# TC37XPD register map
Vendor: Infineon; Series: ATVMC; File version: 100
CPU: other r0p0, little endian, MPU, FPU, vendor SysTick, 4 interrupt priority bits
Registers are 32-bit, read-write, reset 0x0 unless marked. A register's access mark holds for its fields unless they carry their own. Offsets are from the block's base; [hi:lo] are bit positions; lines under a group give offsets from that group; {n}, {i} and the like mark numbered series; 'fields as' and 'values as' point back to an identical list.

## CPU0 (part 2 of 2) — CPU
Base 0xF8800000
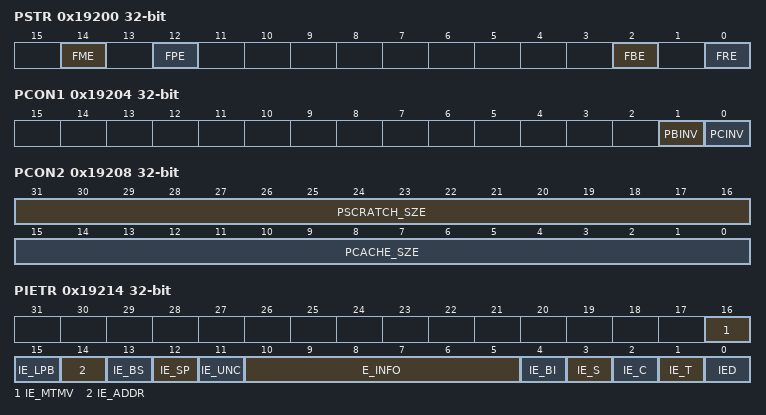
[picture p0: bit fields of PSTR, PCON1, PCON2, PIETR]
0x19200 PSTR — CPUx Program Synchronous Trap Register resetvalue={Application Reset:0x0}
  [14] FME — Fetch MSIST Error FME. During SIST mode a fetch from the PTAG will cause a PSE trap to occur.
  [12] FPE — Fetch Peripheral Error FPE. A Fetch peripheral error will be flagged whenever a fetch is attempted to peripheral space.
  [2] FBE — Fetch Bus Error FBE. A Fetch bus error will be set whenever the SRI flags an error due a fetch from external memory. This will be set for both direct fetches from the bus and for cache refills.
  [0] FRE — Fetch Range Error FRE. A Fetch Range Error occurs whenever an access to the Program Scratch is outside the range of the SRAM.
0x19204 PCON1 — CPUx Program Control 1 resetvalue={Application Reset:0x0}
  [1] PBINV — Program Buffer Invalidate PBINV. Write Operation This field returns 0 when read.
  [0] PCINV — Program Cache Invalidate PCINV
0x19208 PCON2 ro reset not defined — CPUx Program Control 2 resetvalue={Application Reset:0x0}
  [31:16] PSCRATCH_SZE — Program Scratch Size in KBytes PSCRATCH SZE. In KBytes
  [15:0] PCACHE_SZE — Program Cache Size ICACHE in KBytes PCACHE SZE. In KBytes
0x1920C PCON0 reset 0x2 — CPUx Program Control 0 resetvalue={Application Reset:0x2}
  [1] PCBYP — Program Cache Bypass PCBYP
0x19210 PIEAR ro — CPUx Program Integrity Error Address Register resetvalue={Application Reset:0x0}
  [31:0] TA — Transaction Address TA. Physical address being accessed by operation that encountered program integrity error.
0x19214 PIETR access per field — CPUx Program Integrity Error Trap Register resetvalue={Application Reset:0x0}
  [16] IE_MTMV ro — Memory Test Mode Violation detected IE MTMV
  [15] IE_LPB ro — Integrity Error Local Pflash bank IE LPB
  [14] IE_ADDR ro — Address Phase error detected at SRI slave interface IE ADDR
  [13] IE_BS ro — Bus Slave Access Indicator IE BS
  [12] IE_SP ro — Safety Protection Error Detected IE SP
  [11] IE_UNC ro — Integrity Error Uncorrectable Error Detected IE UNC
  [10:5] E_INFO ro — Error Information E INFO. If IE BS 1 Bus Master Tag ID of requesting masterIf IE C 1 Cache way.
  [4] IE_BI ro — Integrity Error Bus Interface IE BI
  [3] IE_S ro — Integrity Error Scratchpad Memory IE S
  [2] IE_C ro — Integrity Error Cache Memory IE C
  [1] IE_T ro — Integrity Error TAG Memory IE T
  [0] IED rw — Integrity Error Detected IED
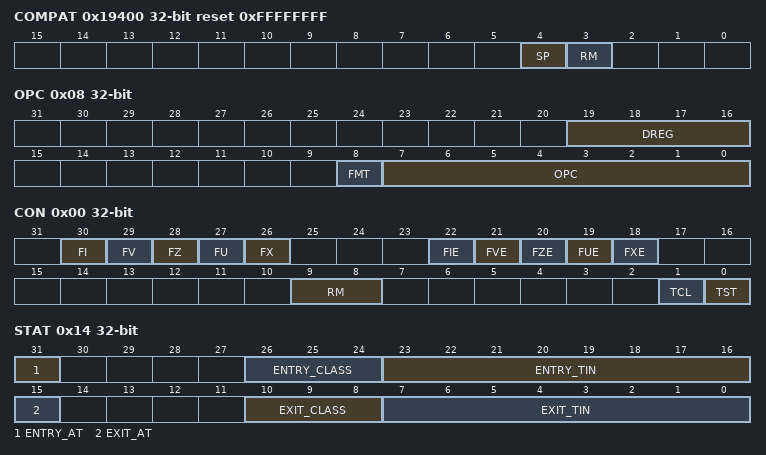
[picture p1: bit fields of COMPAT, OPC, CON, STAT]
0x19400 COMPAT reset 0xFFFFFFFF — CPUx Compatibility Control Register resetvalue={Application Reset:0x0FFFFFFFF}
  [4] SP — SYSCON Safety Protection Mode Compatibility SP
  [3] RM — Rounding Mode Compatibility RM
0x1A000 FPU_TRAP group
  0x00 CON access per field — CPUx Trap Control Register resetvalue={Application Reset:0x0}
    [30] FI ro — Captured FI FI. Asserted if the captured instruction asserted FI. Only valid when TST is asserted
    [29] FV ro — Captured FV FV. Asserted if the captured instruction asserted FV. Only valid when TST is asserted
    [28] FZ ro — Captured FZ FZ. Asserted if the captured instruction asserted FZ. Only valid when TST is asserted
    [27] FU ro — Captured FU FU. Asserted if the captured instruction asserted FU. Only valid when TST is asserted.
    [26] FX ro — Captured FX FX. Asserted if the captured instruction asserted FX. Only valid when TST is asserted.
    [22] FIE rw — FI Trap Enable FIE. When set an instruction generating an FI exception will trigger a trap.
    [21] FVE rw — FV Trap Enable FVE. When set an instruction generating an FV exception will trigger a trap.
    [20] FZE rw — FZ Trap Enable FZE. When set an instruction generating an FZ exception will trigger a trap.
    [19] FUE rw — FU Trap Enable FUE. When set an instruction generating an FU exception will trigger a trap.
    [18] FXE rw — FX Trap Enable FXE. When set an instruction generating an FX exception will trigger a trap.
    [9:8] RM ro — Captured Rounding Mode RM. The rounding mode of the captured instruction. Only valid when TST is asserted. Note that this is the rounding mode supplied to the FPU for the exceptional instruction. UPDFL instructions may cause a trap and change the rounding mode. In this case the RM bits capture the input rounding mode
    [1] TCL wo — Trap Clear TCL. Read always reads as 0.
    [0] TST ro — Trap Status TST
  0x04 PC ro — CPUx Trapping Instruction Program Counter Register resetvalue={Application Reset:0x0}
    [31:0] PC — Captured Program Counter PC. The program counter virtual address of the captured instruction. Only valid when FPU TRAP CON.TST is asserted.
  0x08 OPC ro — CPUx Trapping Instruction Opcode Register resetvalue={Application Reset:0x0}
    [19:16] DREG — Captured Destination Register DREG. The destination register of the captured instruction. ... Only valid when FPU TRAP CON.TST is asserted.
    [8] FMT — Captured Instruction Format FMT. The format of the captured instruction s opcode. Only valid when FPU TRAP CON.TST is asserted.
    [7:0] OPC — Captured Opcode OPC. The secondary opcode of the captured instruction. When FPU TRAP OPC.FMT 0 only bits 3 0 are defined. OPC is valid only when FPU TRAP CON.TST is asserted.
  0x10 SRC1 ro — CPUx Trapping Instruction Operand Register resetvalue={Application Reset:0x0}
    [31:0] SRC1 — Captured SRC1 Operand SRC1. The SRC1 operand of the captured instruction. Only valid when FPU TRAP CON.TST is asserted.
  0x14 SRC2 ro — CPUx Trapping Instruction Operand Register resetvalue={Application Reset:0x0}
    [31:0] SRC2 — Captured SRC2 Operand SRC2. The SRC2 operand of the captured instruction. Only valid when FPU TRAP CON.TST is asserted.
  0x18 SRC3 ro — CPUx Trapping Instruction Operand Register resetvalue={Application Reset:0x0}
    [31:0] SRC3 — Captured SRC3 Operand SRC3. The SRC3 operand of the captured instruction. Only valid when FPU TRAP CON.TST is asserted.
{0x1C000+8i} DPR[{i}] (i=0..17) group
  0x00 DPRy_L — CPUx Data Protection Range 0 Lower Bound Register resetvalue={Application Reset:0x0}
    [31:3] LOWBND — DPRy Lower Boundary Address LOWBND
  0x04 DPRy_U — CPUx Data Protection Range 0 Upper Bound Register resetvalue={Application Reset:0x0}
    [31:3] UPPBND — DPRy Upper Boundary Address UPPBND
{0x1D000+8i} CPR[{i}] (i=0..9) group
  0x00 CPRy_L — CPUx Code Protection Range 0 Lower Bound Register resetvalue={Application Reset:0x0}
    [31:5] LOWBND — CPRy Lower Boundary Address LOWBND
  0x04 CPRy_U — CPUx Code Protection Range 0 Upper Bound Register resetvalue={Application Reset:0x0}
    [31:5] UPPBND — CPR0 m Upper Boundary Address UPPBND
0x1E000 CPXE_0 — CPUx Code Protection Execute Enable Register Set 3 resetvalue={Application Reset:0x0}
  [9:0] XE_n — Execute Enable Range select XE n
0x1E004 CPXE_1 — CPUx Code Protection Execute Enable Register Set 3 resetvalue={Application Reset:0x0}
  [9:0] XE_n — Execute Enable Range select XE n
0x1E008 CPXE_2 — CPUx Code Protection Execute Enable Register Set 3 resetvalue={Application Reset:0x0}
  [9:0] XE_n — Execute Enable Range select XE n
0x1E00C CPXE_3 — CPUx Code Protection Execute Enable Register Set 3 resetvalue={Application Reset:0x0}
  [9:0] XE_n — Execute Enable Range select XE n
0x1E010 DPRE_0 — CPUx Data Protection Read Enable Register Set 3 resetvalue={Application Reset:0x0}
  [17:0] RE_n — Read Enable Range Select RE n
0x1E014 DPRE_1 — CPUx Data Protection Read Enable Register Set 3 resetvalue={Application Reset:0x0}
  [17:0] RE_n — Read Enable Range Select RE n
0x1E018 DPRE_2 — CPUx Data Protection Read Enable Register Set 3 resetvalue={Application Reset:0x0}
  [17:0] RE_n — Read Enable Range Select RE n
0x1E01C DPRE_3 — CPUx Data Protection Read Enable Register Set 3 resetvalue={Application Reset:0x0}
  [17:0] RE_n — Read Enable Range Select RE n
0x1E020 DPWE_0 — CPUx Data Protection Write Enable Register Set 3 resetvalue={Application Reset:0x0}
  [17:0] WE_n — Write Enable Range Select WE n
0x1E024 DPWE_1 — CPUx Data Protection Write Enable Register Set 3 resetvalue={Application Reset:0x0}
  [17:0] WE_n — Write Enable Range Select WE n
0x1E028 DPWE_2 — CPUx Data Protection Write Enable Register Set 3 resetvalue={Application Reset:0x0}
  [17:0] WE_n — Write Enable Range Select WE n
0x1E02C DPWE_3 — CPUx Data Protection Write Enable Register Set 3 resetvalue={Application Reset:0x0}
  [17:0] WE_n — Write Enable Range Select WE n
0x1E040 CPXE_4 — CPUx Code Protection Execute Enable Register Set 5 resetvalue={Application Reset:0x0}
  [9:0] XE_n — Execute Enable Range select XE n
0x1E044 CPXE_5 — CPUx Code Protection Execute Enable Register Set 5 resetvalue={Application Reset:0x0}
  [9:0] XE_n — Execute Enable Range select XE n
0x1E050 DPRE_4 — CPUx Data Protection Read Enable Register Set 5 resetvalue={Application Reset:0x0}
  [17:0] RE_n — Read Enable Range Select RE n
0x1E054 DPRE_5 — CPUx Data Protection Read Enable Register Set 5 resetvalue={Application Reset:0x0}
  [17:0] RE_n — Read Enable Range Select RE n
0x1E060 DPWE_4 — CPUx Data Protection Write Enable Register Set 5 resetvalue={Application Reset:0x0}
  [17:0] WE_n — Write Enable Range Select WE n
0x1E064 DPWE_5 — CPUx Data Protection Write Enable Register Set 5 resetvalue={Application Reset:0x0}
  [17:0] WE_n — Write Enable Range Select WE n
0x1E400 TPS group
  0x00 CON ro — CPUx Temporal Protection System Control Register resetvalue={Application Reset:0x0}
    [16] TTRAP — Temporal Protection Trap TTRAP. If set indicates that a TAE trap has been requested. Any subsequent TAE traps are disabled. A write clears the flag and re enables TAE traps.
    [2] TEXP2 — Timer1 Expired Flag TEXP2. Set when the corresponding timer expires. Cleared on any write to the TIMER1 register.
    [1] TEXP1 — Timer1 Expired Flag TEXP1. Set when the corresponding timer expires. Cleared on any write to the TIMER1 register.
    [0] TEXP0 — Timer0 Expired Flag TEXP0. Set when the corresponding timer expires. Cleared on any write to the TIMER0 register.
  {0x4+4j} TIMER[{j}] (j=0..2) — CPUx Temporal Protection System Timer Register 0 resetvalue={Application Reset:0x0}
    [31:0] Timer — Temporal Protection Timer Timer. Writing zero de activates the Timer. Writing a non zero value starts the Timer. Any write clears the corresponding TPS CON.TEXP flag. Read returns the current Timer value.
0x1E440 TPS_EXTIM group
  0x00 ENTRY_LVAL — CPUx Exception Entry Timer Load Value resetvalue={Application Reset:0x0}
    [11:4] ENTRY_LVAL — Exception Entry Timer Load value ENTRY LVAL. Value loaded into the exception entry timer on detection of an enabled exception. Bits 3 0 are constrained to be 0
  0x04 ENTRY_CVAL ro — CPUx Exception Entry Timer Current Value resetvalue={Application Reset:0x0}
    [11:0] ENTRY_CVAL — Exception Entry Timer Current Value ENTRY CVAL. Current value of the exception entry timer.
  0x08 EXIT_LVAL — CPUx Exception Exit Timer Load Value resetvalue={Application Reset:0x0}
    [23:4] EXIT_LVAL — Exception Exit Timer Load value EXIT LVAL. Value loaded into the exception exit timer on detection of an enabled exception. Bits 3 0 are constrained to be 0
  0x0C EXIT_CVAL ro — CPUx Exception Exit Timer Current Value resetvalue={Application Reset:0x0}
    [23:0] EXIT_CVAL — Exception Exit Timer Current Value EXIT CVAL. Current value of the exception exit timer.
  0x10 CLASS_EN — CPUx Exception Timer Class Enable Register resetvalue={Application Reset:0x0}
    [7:0] EXTIM_CLASS_EN — Exception Timer Class Enables EXTIM CLASS EN. Trap Class enables for exception timer.
  0x14 STAT access per field — CPUx Exception Timer Status Register resetvalue={Application Reset:0x0}
    [31] ENTRY_AT ro — Exception Entry Timer Alarm Triggered ENTRY AT. Exception Entry Timer Alarm triggered sticky bit. Alarm triggered since last cleared.
    [26:24] ENTRY_CLASS rw — Exception Entry Timer Class ENTRY CLASS. Exception Entry Timer Class of triggering trap.
    [23:16] ENTRY_TIN rw — Exception Entry Timer TIN ENTRY TIN. Exception Entry Timer TIN of triggering trap.
    [15] EXIT_AT ro — Exception Exit Timer Alarm Triggered EXIT AT. Exception Exit Timer Alarm triggered sticky bit. Alarm triggered since last cleared.
    [10:8] EXIT_CLASS rw — Exception Exit Timer Class EXIT CLASS. Exception exit Timer Class of triggering trap.
    [7:0] EXIT_TIN rw — Exception Exit Timer TIN EXIT TIN. Exception Exit Timer TIN of triggering trap.
  0x18 FCX ro — CPUx Exception Timer FCX Register resetvalue={Application Reset:0x0}
    [19:0] EXIT_FCX — Exception Exit Timer FCX EXIT FCX. Exception Exit Timer FCX of triggering trap.
{0x1F000+8i} TR[{i}] (i=0..7) group — Trigger
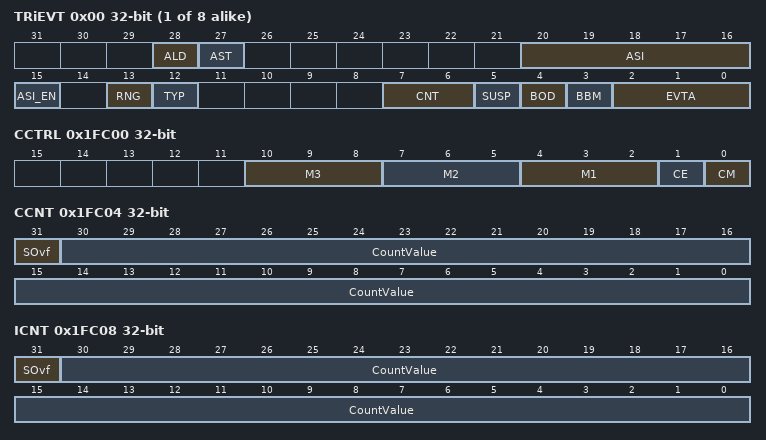
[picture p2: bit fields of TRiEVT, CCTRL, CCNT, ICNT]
  0x00 TRiEVT — CPUx Trigger Event 0 resetvalue={Debug Reset:0x0}
    [28] ALD — Address Load ALD. Used in conjunction with TYP 0
    [27] AST — Address Store AST. Used in conjunction with TYP 0
    [20:16] ASI — Address Space Identifier ASI. The ASI of the Debug Trigger process.
    [15] ASI_EN — Enable ASI Comparison ASI EN
    [13] RNG — Compare Type RNG. Once an even numbered comparator has been set to range the EVTR settings of its associated upper neighbour will be ignored.
    [12] TYP — Input Selection TYP
    [7:6] CNT — Counter CNT. When this event occurs adjust the control of the performance counters in task mode as follows
    [5] SUSP — CDC Suspend Out Signal State SUSP. Value to be assigned to the CDC suspend out signal when the Debug Event is raised.
    [4] BOD — Breakout Disable BOD
    [3] BBM — Break Before Make BBM or Break After Make BAM Selection BBM. Code triggers BBM or BAM selection. Data access and data code combination access triggers can only create BAM Debug Events. When these triggers occur TRnEVT.BBM is ignored.
    [2:0] EVTA — Event Associated EVTA. Specifies the Debug Action associated with the Debug Event
  0x04 TRiADR — CPUx Trigger Address 0 resetvalue={Debug Reset:0x0}
    [31:0] ADDR — Comparison Address ADDR. For PC comparison bit 0 is always zero.
0x1FC00 CCTRL — CPUx Counter Control resetvalue={Debug Reset:0x0}
  [10:8] M3 — M3CNT Configuration M3
  [7:5] M2 — M2CNT Configuration M2
  [4:2] M1 — M1CNT Configuration M1
  [1] CE — Count Enable CE
  [0] CM — Counter Mode CM
0x1FC04 CCNT — CPUx CPU Clock Cycle Count resetvalue={Debug Reset:0x0}
  [31] SOvf — Sticky Overflow Bit SOvf. This bit is set by hardware when count value 30 0 31 h7FFF FFFF. It can only be cleared by software.
  [30:0] CountValue — Count Value CountValue. Current Count of the CPU Clock Cycles.
0x1FC08 ICNT — CPUx Instruction Count resetvalue={Debug Reset:0x0}
  [31] SOvf — Sticky Overflow Bit SOvf. This bit is set by hardware when count value 30 0 31 h7FFF FFFF. It can only be cleared by software.
  [30:0] CountValue — Count Value CountValue. Count of the Instructions Executed.
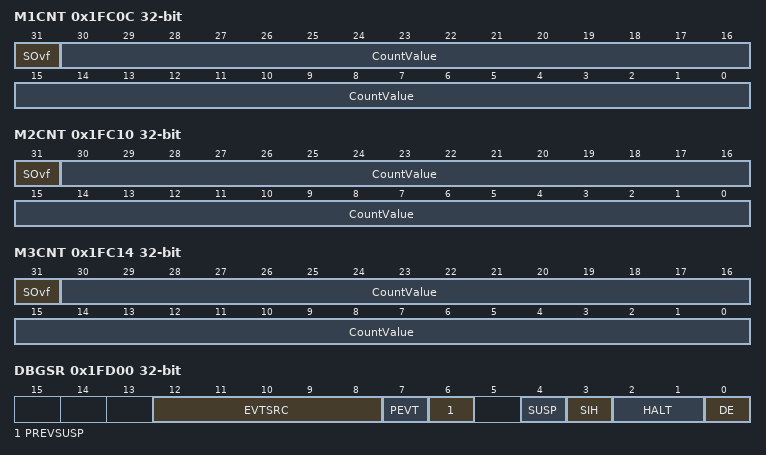
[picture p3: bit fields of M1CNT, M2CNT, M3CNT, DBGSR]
0x1FC0C M1CNT — CPUx Multi Count Register 1 resetvalue={Debug Reset:0x0}
  [31] SOvf — Sticky Overflow Bit SOvf. This bit is set by hardware when count value 30 0 31 h7FFF FFFF. It can only be cleared by software.
  [30:0] CountValue — Count Value CountValue. Count of the Selected Event.
0x1FC10 M2CNT — CPUx Multi Count Register 2 resetvalue={Debug Reset:0x0}
  fields as M1CNT
0x1FC14 M3CNT — CPUx Multi Count Register 3 resetvalue={Debug Reset:0x0}
  fields as M1CNT
0x1FD00 DBGSR access per field — CPUx Debug Status Register resetvalue={Debug Reset:0x0}
  [12:8] EVTSRC ro — Event Source EVTSRC. ... Other Reserved.
  [7] PEVT rw — Posted Event PEVT
  [6] PREVSUSP ro — Previous State of Core Suspend Out Signal PREVSUSP. Updated when a Debug Event causes a hardware update of DBGSR.SUSP. This field is not updated for writes to DBGSR.SUSP.
  [4] SUSP rw — Current State of the Core Suspend Out Signal SUSP
  [3] SIH ro — Suspend in Halt SIH. State of the Suspend In signal.
  [2:1] HALT rw — CPU Halt Request Status Field HALT. HALT can be set or cleared by software. HALT 0 is the actual Halt bit. HALT 1 is a mask bit to specify whether or not HALT 0 is to be updated on a software write. HALT 1 is always read as 0. HALT 1 must be set to 1 in order to update HALT 0 by software R read W write .
  [0] DE ro — Debug Enable DE. Determines whether the CDC is enabled or not.
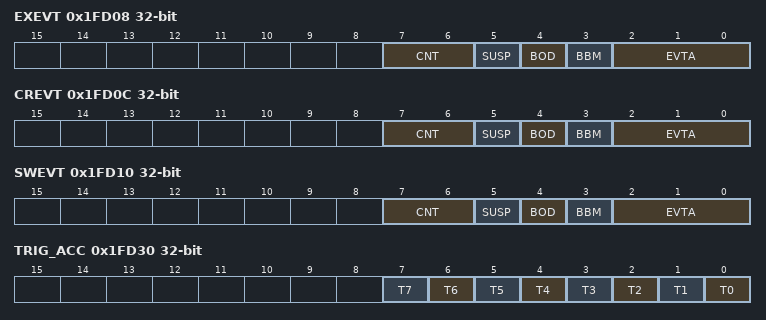
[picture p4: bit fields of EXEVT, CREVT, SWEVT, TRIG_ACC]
0x1FD08 EXEVT — CPUx External Event Register resetvalue={Debug Reset:0x0}
  [7:6] CNT — Counter CNT. When this event occurs adjust the control of the performance counters in task mode as follows
  [5] SUSP — CDC Suspend Out Signal State SUSP. Value to be assigned to the CDC suspend out signal when the Debug Event is raised.
  [4] BOD — Breakout Disable BOD
  [3] BBM — Break Before Make BBM or Break After Make BAM Selection BBM
  [2:0] EVTA — Event Associated EVTA. Specifies the Debug Action associated with the Debug Event
0x1FD0C CREVT — CPUx Core Register Access Event resetvalue={Debug Reset:0x0}
  [7:6] CNT — Counter CNT. When this event occurs adjust the control of the performance counters in task mode as follows
  [5] SUSP — CDC Suspend Out Signal State SUSP. Value to be assigned to the CDC suspend out signal when the Debug Event is raised.
  [4] BOD — Breakout Disable BOD
  [3] BBM — Break Before Make BBM or Break After Make BAM Selection BBM
  [2:0] EVTA — Event Associated EVTA. Debug Action associated with the Debug Event
0x1FD10 SWEVT — CPUx Software Debug Event resetvalue={Debug Reset:0x0}
  [7:6] CNT — Counter CNT. When this event occurs adjust the control of the performance counters in task mode as follows
  [5] SUSP — CDC Suspend Out Signal State SUSP. Value to be assigned to the CDC suspend out signal when the event is raised.
  [4] BOD — Breakout Disable BOD
  [3] BBM — Break Before Make BBM or Break After Make BAM Selection BBM
  [2:0] EVTA — Event Associated EVTA. Debug Action associated with the Debug Event
0x1FD30 TRIG_ACC ro — CPUx TriggerAddressx resetvalue={Debug Reset:0x0}
  [n] T{n} (n=0..7) — Trigger {n} T{n}. active since last cleared
0x1FD40 DMS reset 0xA0000A00 (reset mask 0xFFFFFE3F) — CPUx Debug Monitor Start Address resetvalue={Debug Reset:0x0A0000A00}
  [31:1] DMSValue — Debug Monitor Start Address DMSValue. The address at which monitor code execution begins when a breakpoint trap is taken.
0x1FD44 DCX reset 0xA0000200 (reset mask 0xFFFFFE3F) — CPUx Debug Context Save Area Pointer resetvalue={Debug Reset:0x0A0000200}
  [31:6] DCXValue — Debug Context Save Area Pointer DCXValue. Address where the debug context is stored following a breakpoint trap.
0x1FD48 DBGTCR reset 0x1 — CPUx Debug Trap Control Register resetvalue={Application Reset:0x1}
  [0] DTA — Debug Trap Active Bit DTA. A breakpoint trap may only be taken in the condition DTA 0. Taking a breakpoint trap sets the DTA bit to one. Further breakpoint traps are therefore disabled until such time as the breakpoint trap handler clears the DTA bit or until the breakpoint trap handler terminates with a RFM.
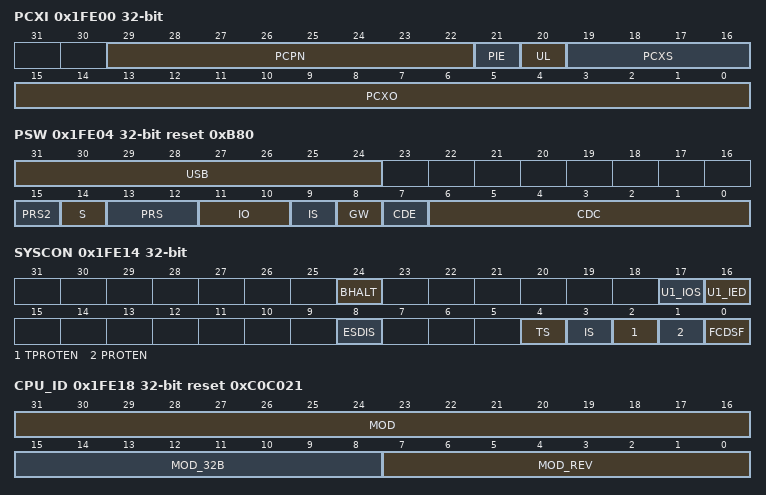
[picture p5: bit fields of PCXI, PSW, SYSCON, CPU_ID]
0x1FE00 PCXI — CPUx Previous Context Information Register resetvalue={Application Reset:0x0}
  [29:22] PCPN — Previous CPU Priority Number PCPN. Contains the priority level number of the interrupted task.
  [21] PIE — Previous Interrupt Enable PIE. Indicates the state of the interrupt enable bit ICR.IE for the interrupted task.
  [20] UL — Upper or Lower Context Tag UL. Identifies the type of context saved. If the type does not match the type expected when a context restore operation is performed a trap is generated.
  [19:16] PCXS — Previous Context Pointer Segment Address PCXS. Contains the segment address portion of the PCX. This field is used in conjunction with the PCXO field.
  [15:0] PCXO — Previous Context Pointer Offset Field PCXO. The PCXO and PCXS fields form the pointer PCX which points to the CSA of the previous context.
0x1FE04 PSW reset 0xB80 — CPUx Program Status Word resetvalue={Application Reset:0x0B80}
  [31:24] USB — User Status Bits USB. The eight most significant bits of the PSW are designated as User Status Bits. These bits may be set or cleared as side effects of instruction execution. Refer to the TriCore Architecture manual for details.
  [15] PRS2 — Protection Register Set MSB PRS2. Selects the active Data and Code Memory Protection Register Set. The memory protection register values control load store and instruction fetches within the current process. PRS values 111 and 110 are reserved
  [14] S — Safe Task Identifier S
  [13:12] PRS — Protection Register Set PRS. Selects the active Data and Code Memory Protection Register Set. The memory protection register values control load store and instruction fetches within the current process. PRS values 111 and 110 are reserved
  [11:10] IO — Access Privilege Level Control I O Privilege IO. Determines the access level to special function registers and peripheral devices.
  [9] IS — Interrupt Stack Control IS. Determines if the current execution thread is using the shared global interrupt stack or a user stack.
  [8] GW — Global Address Register Write Permission GW. Determines whether the current execution thread has permission to modify the global address registers.Most tasks and ISRs use the global address registers as read only registers pointing to the global literal pool and key data structures. However a task or ISR can be designated as the owner of a particular global address register and is allowed to modify it. The system designer must determine which global address variables are used with sufficient frequency and or in sufficiently time critical code to justify allocation to a global address register. By compiler convention global address register A 0 is reserved as the base register for short form loads and stores. Register A 1 is also reserved for compiler use.Registers A 8 and A 9 are not used by the compiler and are available for holding critical system address variables.
  [7] CDE — Call Depth Count Enable CDE. Enables call depth counting provided that the PSW.CDC mask field is not all set to 1. If PSW.CDC 1111111 B call depth counting is disabled regardless of the setting on the PSW.CDE bit.
  [6:0] CDC — Call Depth Counter CDC. Consists of two variable width subfields. The first subfield consists of a string of zero or more initial 1 bits terminated by the first 0 bit. The remaining bits form the second subfield CDC.COUNT which constitutes the Call Depth Count value. The count value is incremented on each Call and is decremented on a Return. 0cccccc B 6 bit counter trap on overflow. 10ccccc B 5 bit counter trap on overflow. 110cccc B 4 bit counter trap on overflow. 1110ccc B 3 bit counter trap on overflow. 11110cc B 2 bit counter trap on overflow. 111110c B 1 bit counter trap on overflow. 1111110 B Trap every call Call Trace mode . 1111111 B Disable Call Depth Counting. When the call depth count CDC.COUNT overflows a trap CDO is generated. Setting the CDC to 1111110 B allows no bits for the counter and causes every call to be trapped. This is used for Call Depth Tracing. Setting the CDC to 1111111 B disables Call Depth Counting.
0x1FE08 PC reset not defined — CPUx Program Counter resetvalue={Application Reset:0x0}
  [31:1] PC — Program Counter PC
0x1FE14 SYSCON reset not defined — CPUx System Configuration Register resetvalue={Application Reset:0x0,Application Reset:0x0}
  [24] BHALT — Boot Halt BHALT
  [17] U1_IOS — User 1 Peripheral access as supervisor U1 IOS. Allow User 1 mode tasks to access peripherals as if in Supervisor mode. Enables User 1 access to all peripheral registers.
  [16] U1_IED — User 1 Instruction execution disable U1 IED. Disable the execution of User 1 mode instructions in User 1 IO mode. Disables User 1 ability to enable and disable interrupts.
  [8] ESDIS — Emulator Space Disable. Disable the Emulator Space system
  [4] TS — Initial State Trap TS. of PSW.S bit in trap handle
  [3] IS — Initial State Interrupt IS. of PSW.S bit in interrupt handle
  [2] TPROTEN — Temporal Protection Enable TPROTEN. Enable the Temporal Protection system.
  [1] PROTEN — Memory Protection Enable PROTEN. Enables the memory protection system. Memory protection is controlled through the memory protection register sets. Note Initialize the protection register sets prior to setting PROTEN to one.
  [0] FCDSF — Free Context List Depleted Sticky Flag FCDSF. This sticky bit indicates that a FCD Free Context List Depleted trap occurred since the bit was last cleared by software.
0x1FE18 CPU_ID ro reset 0xC0C021 — CPUx Identification Register TC1.6.2P resetvalue={Application Reset:0x0C0C021}
  [31:16] MOD — Module Identification Number MOD
  [15:8] MOD_32B — 32 Bit Module Enable MOD 32B
  [7:0] MOD_REV — Revision Number MOD REV
0x1FE1C CORE_ID ro (reset mask 0xFFFFFFF8) — CPUx Core Identification Register resetvalue={Application Reset:0x0}
  [2:0] CORE_ID — Core Identification Number CORE ID. The identification number of the core.
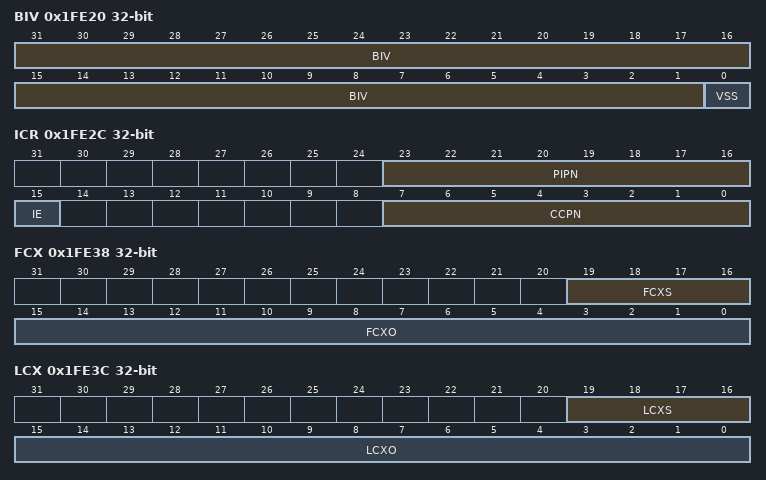
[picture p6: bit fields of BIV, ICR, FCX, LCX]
0x1FE20 BIV — CPUx Base Interrupt Vector Table Pointer resetvalue={Application Reset:0x0}
  [31:1] BIV — Base Address of Interrupt Vector Table BIV. The address in the BIV register must be aligned to an even byte address halfword address . Because of the simple ORing of the left shifted priority number and the contents of the BIV register the alignment of the base address of the vector table must be to a power of two boundary dependent on the number of interrupt entries used. For the full range of 256 interrupt entries an alignment to an 8 KByte boundary is required. If fewer sources are used the alignment requirements are correspondingly relaxed.
  [0] VSS — Vector Spacing Select VSS. 0 32 byte vector spacing. 1 8 Byte vector spacing.
0x1FE24 BTV reset 0xA0000100 — CPUx Base Trap Vector Table Pointer resetvalue={Application Reset:0x0A0000100}
  [31:1] BTV — Base Address of Trap Vector Table BTV. The address in the BTV register must be aligned to an even byte address halfword address . Also due to the simple ORing of the left shifted trap identification number and the contents of the BTV register the alignment of the base address of the vector table must be to a power of two boundary. There are eight different trap classes resulting in Trap Classes from 0 to 7. The contents of BTV should therefore be set to at least a 256 byte boundary 8 Trap Classes 8 word spacing .
0x1FE28 ISP reset 0x100 — CPUx Interrupt Stack Pointer resetvalue={Application Reset:0x100}
  [31:0] ISP — Interrupt Stack Pointer ISP
0x1FE2C ICR access per field — CPUx Interrupt Control Register resetvalue={Application Reset:0x0}
  [23:16] PIPN ro — Pending Interrupt Priority Number PIPN. A read only bit field that is updated by the ICU at the end of each interrupt arbitration process. It indicates the priority number of the pending service request. ICR.PIPN is set to 0 when no request is pending and at the beginning of each new arbitration process. ...
  [15] IE rw — Global Interrupt Enable Bit IE. The interrupt enable bit globally enables the CPU service request system. Whether a service request is delivered to the CPU depends on the individual Service Request Enable Bits SRE in the SRNs and the current state of the CPU. ICR.IE is automatically updated by hardware on entry and exit of an Interrupt Service Routine ISR . ICR.IE is cleared to 0 when an interrupt is taken and is restored to the previous value when the ISR executes an RFE instruction to terminate itself. ICR.IE can also be updated through the execution of the ENABLE DISABLE MTCR and BISR instructions.
  [7:0] CCPN rw — Current CPU Priority Number CCPN. The Current CPU Priority Number CCPN bit field indicates the current priority level of the CPU. It is automatically updated by hardware on entry or exit of Interrupt Service Routines ISRs and through the execution of a BISR instruction. CCPN can also be updated through an MTCR instruction.
0x1FE38 FCX — CPUx Free CSA List Head Pointer resetvalue={Application Reset:0x0}
  [19:16] FCXS — FCX Segment Address Field FCXS. Used in conjunction with the FCXO field.
  [15:0] FCXO — FCX Offset Address Field FCXO. The FCXO and FCXS fields together form the FCX pointer which points to the next available CSA.
0x1FE3C LCX — CPUx Free CSA List Limit Pointer resetvalue={Application Reset:0x0}
  [19:16] LCXS — LCX Segment Address LCXS. This field is used in conjunction with the LCXO field.
  [15:0] LCXO — LCX Offset Field LCXO. The LCXO and LCXS fields form the pointer LCX which points to the last available CSA.
0x1FE50 CUS_ID ro (reset mask 0xFFFFFFF8) — CPUx Customer ID register resetvalue={Application Reset:0x0}
  [2:0] CID — Customer ID CID. See CROSSREFERENCE for the relation between CUS ID and CORE ID for each derivative
{0x1FF00+4i} Dy[{i}] (i=0..15) — CPUx Data General Purpose Register 0 resetvalue={Application Reset:0x0}
  [31:0] DATA — Data Register DATA. General purpose registers
{0x1FF80+4i} Ay[{i}] (i=0..15) — CPUx Address General Purpose Register 0 resetvalue={Application Reset:0x0}
  [31:0] ADDR — Address Register ADDR. General purpose registers

## CPU1 (part 2 of 2) — CPU
Base 0xF8820000
Registers as CPU0.

## CPU2 (part 2 of 2) — CPU
Base 0xF8840000
Registers as CPU0.
